# AT32F403Axx_v2 register map
Vendor: Keil; Series: AT32F403A; File version: 1.0
CPU: CM4 r0p1, little endian, no MPU, FPU, 4 interrupt priority bits
Registers are 32-bit, read-write, reset 0x0 unless marked. A register's access mark holds for its fields unless they carry their own. Offsets are from the block's base; [hi:lo] are bit positions; {n}, {i} and the like mark numbered series.

## GPIOA — General purpose IO
Base 0x40010800
Same registers: GPIOB 0x40010C00, GPIOC 0x40011000, GPIOD 0x40011400, GPIOE 0x40011800
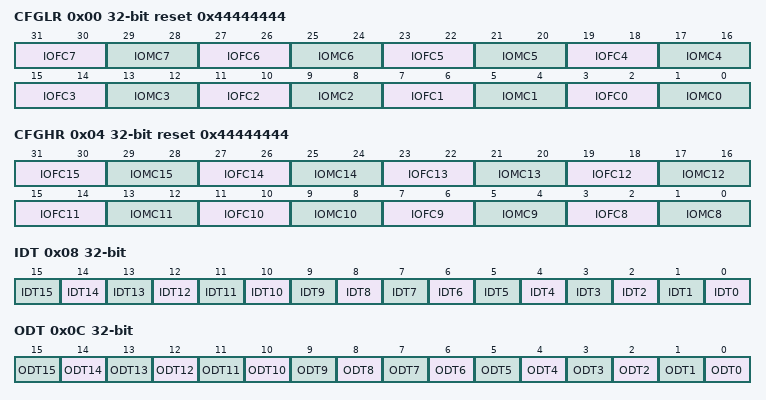
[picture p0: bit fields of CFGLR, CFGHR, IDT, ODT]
0x00 CFGLR reset 0x44444444 — GPIO function configurate low register
  [31:30] IOFC7 — Port n.7 function configurate bits
  [29:28] IOMC7 — Port n.7 mode configurate bits
  [27:26] IOFC6 — Port n.6 function configurate bits
  [25:24] IOMC6 — Port n.6 mode configurate bits
  [23:22] IOFC5 — Port n.5 function configurate bits
  [21:20] IOMC5 — Port n.5 mode configurate bits
  [19:18] IOFC4 — Port n.4 function configurate bits
  [17:16] IOMC4 — Port n.4 mode configurate bits
  [15:14] IOFC3 — Port n.3 function configurate bits
  [13:12] IOMC3 — Port n.3 mode configurate bits
  [11:10] IOFC2 — Port n.2 function configurate bits
  [9:8] IOMC2 — Port n.2 mode configurate bits
  [7:6] IOFC1 — Port n.1 function configurate bits
  [5:4] IOMC1 — Port n.1 mode configurate bits
  [3:2] IOFC0 — Port n.0 function configurate bits
  [1:0] IOMC0 — Port n.0 mode configurate bits
0x04 CFGHR reset 0x44444444 — GPIO function configurate high register
  [31:30] IOFC15 — Port n.15 function configurate bits
  [29:28] IOMC15 — Port n.15 mode configurate bits
  [27:26] IOFC14 — Port n.14 function configurate bits
  [25:24] IOMC14 — Port n.14 mode configurate bits
  [23:22] IOFC13 — Port n.13 function configurate bits
  [21:20] IOMC13 — Port n.13 mode configurate bits
  [19:18] IOFC12 — Port n.12 function configurate bits
  [17:16] IOMC12 — Port n.12 mode configurate bits
  [15:14] IOFC11 — Port n.11 function configurate bits
  [13:12] IOMC11 — Port n.11 mode configurate bits
  [11:10] IOFC10 — Port n.10 function configurate bits
  [9:8] IOMC10 — Port n.10 mode configurate bits
  [7:6] IOFC9 — Port n.9 function configurate bits
  [5:4] IOMC9 — Port n.9 mode configurate bits
  [3:2] IOFC8 — Port n.8 function configurate bits
  [1:0] IOMC8 — Port n.8 mode configurate bits
0x08 IDT ro — Port input data register
  [n] IDT{n} (n=0..15) — Port input data
0x0C ODT — Port output data register
  [n] ODT{n} (n=0..15) — Port output data
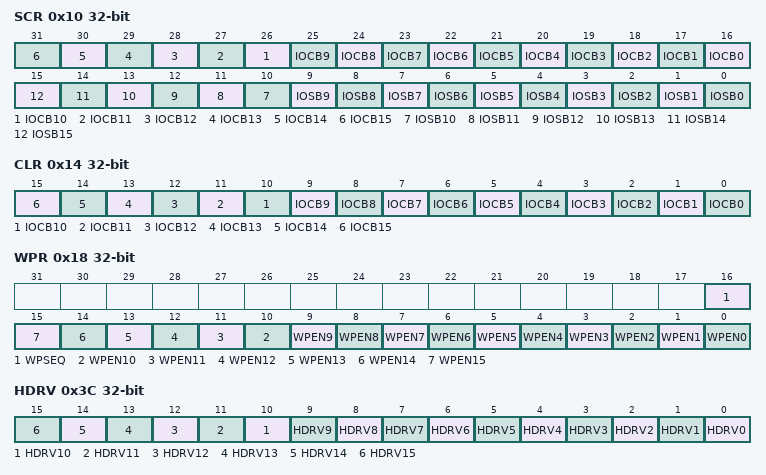
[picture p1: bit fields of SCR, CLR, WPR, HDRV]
0x10 SCR — Port bit set/clear register
  [n+16] IOCB{n} (n=0..15) — Clear bit {n}
  [n] IOSB{n} (n=3..15) — Set bit {n}
  [2] IOSB2 — Set bit 1
  [1] IOSB1 — Set bit 1
  [0] IOSB0 — Set bit 0
0x14 CLR — Port bit reset register
  [n] IOCB{n} (n=3..15) — Clear bit {n}
  [2] IOCB2 — Clear bit 1
  [1] IOCB1 — Clear bit 1
  [0] IOCB0 — Clear bit 0
0x18 WPR — Port write protect register
  [16] WPSEQ — Write protect sequence
  [n] WPEN{n} (n=0..15) — Write protect enable {n}
0x3C HDRV — Port configuration driver register
  [n] HDRV{n} (n=0..15) — Port hdrv bit {n}

## EXINT
Base 0x40010400
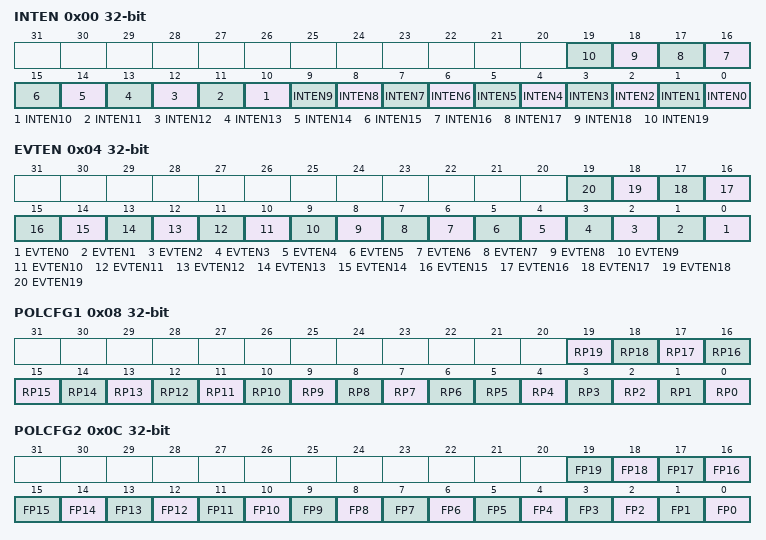
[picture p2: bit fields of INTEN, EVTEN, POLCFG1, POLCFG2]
0x00 INTEN — Interrupt enable register
  [n] INTEN{n} (n=0..19) — Interrupt enable or disable on line {n}
0x04 EVTEN — Event enable register
  [n] EVTEN{n} (n=0..19) — Event enable or disable on line {n}
0x08 POLCFG1 — Rising polarity configuration register
  [n] RP{n} (n=7..19) — Rising polarity configuration bit of line {n}
  [6] RP6 — Rising polarity configuration bit of linee 6
  [n] RP{n} (n=0..5) — Rising polarity configuration bit of line {n}
0x0C POLCFG2 — Falling polarity configuration register
  [n] FP{n} (n=0..19) — Falling polarity event configuration bit of line {n}
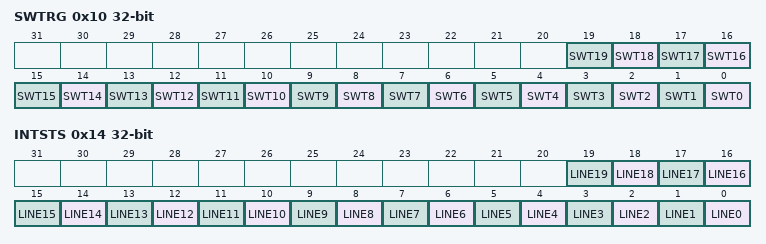
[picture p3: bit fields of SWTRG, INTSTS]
0x10 SWTRG — Software triggle register
  [n] SWT{n} (n=0..19) — Software triggle on line {n}
0x14 INTSTS — Interrupt status register
  [n] LINE{n} (n=0..19) — Line {n} state bit

## RTC — Real time clock
Base 0x40002800
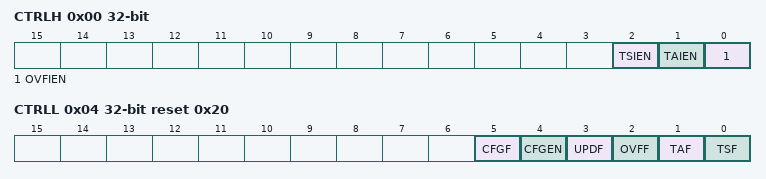
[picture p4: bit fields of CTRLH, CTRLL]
0x00 CTRLH — RTC Control Register High
  [2] TSIEN — Time second interrupt enable
  [1] TAIEN — Time alarm interrupt enable
  [0] OVFIEN — Overflow interrupt enable
0x04 CTRLL reset 0x20 — RTC Control Register Low
  [5] CFGF ro — RTC configuration finish
  [4] CFGEN — RTC configuration enable
  [3] UPDF — RTC update finish
  [2] OVFF — Overflow Flag
  [1] TAF — Time alarm flag
  [0] TSF — Time second flag
0x08 DIVH wo — RTC Divider Register High
  [3:0] DIV — RTC divider high
0x0C DIVL wo reset 0x8000 — RTC Divider Register Low
  [15:0] DIV — RTC divider low
0x10 DIVCNTH — RTC Divider Register High
  [3:0] DIVCNT — RTC divider register high
0x14 DIVCNTL reset 0x8000 — RTC Divider Register Low
  [15:0] DIVCNT — RTC divider register low
0x18 CNTH — RTC Counter Register High
  [15:0] CNT — RTC counter register high
0x1C CNTL — RTC Counter Register Low
  [15:0] CNT — RTC counter register low
0x20 TAH wo reset 0xFFFF — RTC Alarm Register High
  [15:0] TA — Time alarm register high
0x24 TAL wo reset 0xFFFF — Time alarm register low
  [15:0] TA — RTC alarm register low

## Notices in the file
Copyright (C) 2012-2014 ARM Limited. All rights reserved.
Purpose: System Viewer Description (SVD) Example (Schema Version 1.1)
This is a description of a none-existent and incomplete device
for demonstration purposes only.
Redistribution and use in source and binary forms, with or without
modification, are permitted provided that the following conditions are met:
- Redistributions of source code must retain the above copyright
notice, this list of conditions and the following disclaimer.
- Redistributions in binary form must reproduce the above copyright
notice, this list of conditions and the following disclaimer in the
documentation and/or other materials provided with the distribution.
- Neither the name of ARM nor the names of its contributors may be used
to endorse or promote products derived from this software without
specific prior written permission.
THIS SOFTWARE IS PROVIDED BY THE COPYRIGHT HOLDERS AND CONTRIBUTORS "AS IS"
AND ANY EXPRESS OR IMPLIED WARRANTIES, INCLUDING, BUT NOT LIMITED TO, THE
IMPLIED WARRANTIES OF MERCHANTABILITY AND FITNESS FOR A PARTICULAR PURPOSE
ARE DISCLAIMED. IN NO EVENT SHALL COPYRIGHT HOLDERS AND CONTRIBUTORS BE
LIABLE FOR ANY DIRECT, INDIRECT, INCIDENTAL, SPECIAL, EXEMPLARY, OR
CONSEQUENTIAL DAMAGES (INCLUDING, BUT NOT LIMITED TO, PROCUREMENT OF
SUBSTITUTE GOODS OR SERVICES; LOSS OF USE, DATA, OR PROFITS; OR BUSINESS
INTERRUPTION) HOWEVER CAUSED AND ON ANY THEORY OF LIABILITY, WHETHER IN
CONTRACT, STRICT LIABILITY, OR TORT (INCLUDING NEGLIGENCE OR OTHERWISE)
ARISING IN ANY WAY OUT OF THE USE OF THIS SOFTWARE, EVEN IF ADVISED OF THE
POSSIBILITY OF SUCH DAMAGE.
